AUTOSAR XML (schema 00047)
# (C) 2021 HYUNDAI AUTOEVER Corp.
package /Csm/ClientServerInterfaces
  6 x client server interface, all with is-service=true:
    CallbackNotification  # Interface for the callback notification.
      operation CallbackNotification  # Notifies the application with a return value that the job has finished.
        arg result: type=Csm_ResultType, direction=IN  # Return value that shall be returned to the application
    CsmKeyManagement_CryptoKey_Dummy  # Interface to execute the key management functions.
      11 x operation:
        KeyCopy: possible-error=[CsmKeyManagement_CryptoKey_Dummy/CSM_E_BUSY, CsmKeyManagement_CryptoKey_Dummy/CSM_E_KEY_EMPTY, CsmKeyManagement_CryptoKey_Dummy/CSM_E_KEY_NOT_AVAILABLE, CsmKeyManagement_CryptoKey_Dummy/CSM_E_KEY_READ_FAIL, CsmKeyManagement_CryptoKey_Dummy/CSM_E_KEY_SIZE_MISMATCH, CsmKeyManagement_CryptoKey_Dummy/CSM_E_KEY_WRITE_FAIL, CsmKeyManagement_CryptoKey_Dummy/E_NOT_OK, CsmKeyManagement_CryptoKey_Dummy/E_OK]  # This function shall copy all key elements from the source key to a target key.
          arg targetKeyId: type=uint32, direction=IN  # Holds the identifier of the key whose key element shall be the destination element.
        KeyDerive: possible-error=[CsmKeyManagement_CryptoKey_Dummy/CSM_E_BUSY, CsmKeyManagement_CryptoKey_Dummy/CSM_E_KEY_EMPTY, CsmKeyManagement_CryptoKey_Dummy/CSM_E_KEY_READ_FAIL, CsmKeyManagement_CryptoKey_Dummy/CSM_E_KEY_SIZE_MISMATCH, CsmKeyManagement_CryptoKey_Dummy/CSM_E_KEY_WRITE_FAIL, CsmKeyManagement_CryptoKey_Dummy/E_NOT_OK, CsmKeyManagement_CryptoKey_Dummy/E_OK]  # Derives a new key by using the key elements in the given key. The given key contains the key elements for the password and salt. The derived key is stored in the key element with the id 1 of the key identified by targetCryptoKeyId.
          arg targetKeyId: type=uint32, direction=IN  # Holds the identifier of the key which is used to store the derived key.
        KeyElementCopy: possible-error=[CsmKeyManagement_CryptoKey_Dummy/CSM_E_BUSY, CsmKeyManagement_CryptoKey_Dummy/CSM_E_KEY_EMPTY, CsmKeyManagement_CryptoKey_Dummy/CSM_E_KEY_NOT_AVAILABLE, CsmKeyManagement_CryptoKey_Dummy/CSM_E_KEY_READ_FAIL, CsmKeyManagement_CryptoKey_Dummy/CSM_E_KEY_SIZE_MISMATCH, CsmKeyManagement_CryptoKey_Dummy/CSM_E_KEY_WRITE_FAIL, CsmKeyManagement_CryptoKey_Dummy/E_NOT_OK, CsmKeyManagement_CryptoKey_Dummy/E_OK]  # This function shall copy a key elements from one key to a target key
          arg keyElementId: type=uint32, direction=IN  # Holds the identifier of the key element which shall be the source for the copy operation.
          arg targetKeyId: type=uint32, direction=IN  # Holds the identifier of the key whose key element shall be the destination element.
          arg targetKeyElementId: type=uint32, direction=IN  # Holds the identifier of the key element which shall be the destination for the copy operation.
        KeyElementCopyPartial: possible-error=[CsmKeyManagement_CryptoKey_Dummy/CSM_E_BUSY, CsmKeyManagement_CryptoKey_Dummy/CSM_E_KEY_EMPTY, CsmKeyManagement_CryptoKey_Dummy/CSM_E_KEY_NOT_AVAILABLE, CsmKeyManagement_CryptoKey_Dummy/CSM_E_KEY_READ_FAIL, CsmKeyManagement_CryptoKey_Dummy/CSM_E_KEY_SIZE_MISMATCH, CsmKeyManagement_CryptoKey_Dummy/CSM_E_KEY_WRITE_FAIL, CsmKeyManagement_CryptoKey_Dummy/E_NOT_OK, CsmKeyManagement_CryptoKey_Dummy/E_OK]  # This function shall copy parts of a a key elements from one key to parts of a target key element of a target key.
          6 x arg, all with type=uint32, direction=IN:
            keyElementId  # Holds the identifier of the key element which shall be the source for the copy operation.
            keyElementSourceOffset  # This is the offset of the source key element indicating the start index of the copy operation.
            keyElementTargetOffset  # This is the offset of the destination key element indicating the start index of the copy operation.
            keyElementCopyLength  # Specifies the number of bytes that shall be copied.
            targetKeyId  # Holds the identifier of the key whose key element shall be the destination element.
            targetKeyElementId  # Holds the identifier of the key element which shall be the destination for the copy operation.
        KeyElementGet: possible-error=[CsmKeyManagement_CryptoKey_Dummy/CSM_E_BUSY, CsmKeyManagement_CryptoKey_Dummy/CSM_E_KEY_EMPTY, CsmKeyManagement_CryptoKey_Dummy/CSM_E_KEY_NOT_AVAILABLE, CsmKeyManagement_CryptoKey_Dummy/CSM_E_KEY_READ_FAIL, CsmKeyManagement_CryptoKey_Dummy/CSM_E_SMALL_BUFFER, CsmKeyManagement_CryptoKey_Dummy/E_NOT_OK, CsmKeyManagement_CryptoKey_Dummy/E_OK]  # Retrieves the key element bytes from a specific key element of the key and stores the key element in the provided buffer.
          arg keyElementId: type=uint32, direction=IN  # Holds the identifier of the key element to be read.
          arg keyPtr: type=uint8, direction=OUT  # Holds the data to the key element bytes to be written.
          arg keyLength: type=uint32, direction=INOUT  # Contains the number of key element bytes.
        KeyElementSet: possible-error=[CsmKeyManagement_CryptoKey_Dummy/CSM_E_BUSY, CsmKeyManagement_CryptoKey_Dummy/CSM_E_KEY_NOT_AVAILABLE, CsmKeyManagement_CryptoKey_Dummy/CSM_E_KEY_SIZE_MISMATCH, CsmKeyManagement_CryptoKey_Dummy/CSM_E_KEY_WRITE_FAIL, CsmKeyManagement_CryptoKey_Dummy/E_NOT_OK, CsmKeyManagement_CryptoKey_Dummy/E_OK]  # Sets the given key element bytes to the key.
          arg keyElementId: type=uint32, direction=IN  # Holds the identifier of the key element to be written.
          arg keyPtr: type=Csm_ConstDataPtr, direction=IN  # Holds the data to the key element bytes to be processed.
          arg keyLength: type=uint32, direction=IN  # Contains the number of key element bytes.
        KeyExchangeCalcPubVal: possible-error=[CsmKeyManagement_CryptoKey_Dummy/CSM_E_BUSY, CsmKeyManagement_CryptoKey_Dummy/CSM_E_KEY_EMPTY, CsmKeyManagement_CryptoKey_Dummy/CSM_E_SMALL_BUFFER, CsmKeyManagement_CryptoKey_Dummy/E_NOT_OK, CsmKeyManagement_CryptoKey_Dummy/E_OK]  # Calculates the public value of the current user for the key exchange and stores the public key in the provided buffer
          arg publicValuePtr: type=uint8, direction=OUT  # Holds a pointer to the memory location in which the public value length in bytes is stored. On calling this function, this parameter shall contain the size of the buffer in bytes provided by publicValuePtr. When the request has finished, the actual length of the returned value shall be stored.
          arg publicValueLengthPtr: type=uint32, direction=INOUT  # Contains the pointer to the data where the public value shall be stored.
        KeyExchangeCalcSecret: possible-error=[CsmKeyManagement_CryptoKey_Dummy/CSM_E_BUSY, CsmKeyManagement_CryptoKey_Dummy/CSM_E_KEY_EMPTY, CsmKeyManagement_CryptoKey_Dummy/CSM_E_SMALL_BUFFER, CsmKeyManagement_CryptoKey_Dummy/E_NOT_OK, CsmKeyManagement_CryptoKey_Dummy/E_OK]  # Calculates the shared secret key for the key exchange with the key material of the key identified by the keyId and the partner public key. The shared secret key is stored as a key element in the same key.
          arg partnerPublicValuePtr: type=Csm_ConstDataPtr, direction=IN  # Holds the pointer to the memory location containing the partner's public value
          arg partnerPublicValueLength: type=uint32, direction=IN  # Contains the number of bytes of the partner pulic value
        KeyGenerate: possible-error=[CsmKeyManagement_CryptoKey_Dummy/CSM_E_BUSY, CsmKeyManagement_CryptoKey_Dummy/CSM_E_KEY_EMPTY, CsmKeyManagement_CryptoKey_Dummy/E_NOT_OK, CsmKeyManagement_CryptoKey_Dummy/E_OK]  # Generates new key material and store it in the key identified by keyId.
        KeySetValid: possible-error=[CsmKeyManagement_CryptoKey_Dummy/CSM_E_BUSY, CsmKeyManagement_CryptoKey_Dummy/E_NOT_OK, CsmKeyManagement_CryptoKey_Dummy/E_OK]  # Sets the given key element bytes to the key.
        RandomSeed: possible-error=[CsmKeyManagement_CryptoKey_Dummy/CSM_E_BUSY, CsmKeyManagement_CryptoKey_Dummy/E_NOT_OK, CsmKeyManagement_CryptoKey_Dummy/E_OK]  # Feeds the key element CRYPTO_KE_RANDOM_SEED with a random seed.
          arg seedPtr: type=Csm_ConstDataPtr, direction=IN  # Holds the data which shall be used for the random seed initialization.
          arg seedLength: type=uint32, direction=IN  # Contains the length of the seed in bytes.
      9 x error:
        CSM_E_BUSY: error-code=2  # Request failed, service is still busy.
        CSM_E_KEY_EMPTY: error-code=13  # The service request failed because of uninitialized source key element.
        CSM_E_KEY_NOT_AVAILABLE: error-code=8  # The service request failed because the key is not available.
        CSM_E_KEY_READ_FAIL: error-code=6  # The service request failed because read access was denied.
        CSM_E_KEY_SIZE_MISMATCH: error-code=10  # Request failed because the key element is not partially accessible and the provided key element length is too short or too long for that key element.
        CSM_E_KEY_WRITE_FAIL: error-code=7  # The service request failed because write access was denied.
        CSM_E_SMALL_BUFFER: error-code=3  # The provided buffer is too small to store the result.
        E_NOT_OK: error-code=1  # Operation failed
        E_OK: error-code=0  # Operation successful
    CsmKeyManagement_CryptoKey_OEUK  # Interface to execute the key management functions.
      11 x operation:
        KeyCopy: possible-error=[CsmKeyManagement_CryptoKey_OEUK/CSM_E_BUSY, CsmKeyManagement_CryptoKey_OEUK/CSM_E_KEY_EMPTY, CsmKeyManagement_CryptoKey_OEUK/CSM_E_KEY_NOT_AVAILABLE, CsmKeyManagement_CryptoKey_OEUK/CSM_E_KEY_READ_FAIL, CsmKeyManagement_CryptoKey_OEUK/CSM_E_KEY_SIZE_MISMATCH, CsmKeyManagement_CryptoKey_OEUK/CSM_E_KEY_WRITE_FAIL, CsmKeyManagement_CryptoKey_OEUK/E_NOT_OK, CsmKeyManagement_CryptoKey_OEUK/E_OK]  # This function shall copy all key elements from the source key to a target key.
          arg targetKeyId: type=uint32, direction=IN  # Holds the identifier of the key whose key element shall be the destination element.
        KeyDerive: possible-error=[CsmKeyManagement_CryptoKey_OEUK/CSM_E_BUSY, CsmKeyManagement_CryptoKey_OEUK/CSM_E_KEY_EMPTY, CsmKeyManagement_CryptoKey_OEUK/CSM_E_KEY_READ_FAIL, CsmKeyManagement_CryptoKey_OEUK/CSM_E_KEY_SIZE_MISMATCH, CsmKeyManagement_CryptoKey_OEUK/CSM_E_KEY_WRITE_FAIL, CsmKeyManagement_CryptoKey_OEUK/E_NOT_OK, CsmKeyManagement_CryptoKey_OEUK/E_OK]  # Derives a new key by using the key elements in the given key. The given key contains the key elements for the password and salt. The derived key is stored in the key element with the id 1 of the key identified by targetCryptoKeyId.
          arg targetKeyId: type=uint32, direction=IN  # Holds the identifier of the key which is used to store the derived key.
        KeyElementCopy: possible-error=[CsmKeyManagement_CryptoKey_OEUK/CSM_E_BUSY, CsmKeyManagement_CryptoKey_OEUK/CSM_E_KEY_EMPTY, CsmKeyManagement_CryptoKey_OEUK/CSM_E_KEY_NOT_AVAILABLE, CsmKeyManagement_CryptoKey_OEUK/CSM_E_KEY_READ_FAIL, CsmKeyManagement_CryptoKey_OEUK/CSM_E_KEY_SIZE_MISMATCH, CsmKeyManagement_CryptoKey_OEUK/CSM_E_KEY_WRITE_FAIL, CsmKeyManagement_CryptoKey_OEUK/E_NOT_OK, CsmKeyManagement_CryptoKey_OEUK/E_OK]  # This function shall copy a key elements from one key to a target key
          arg keyElementId: type=uint32, direction=IN  # Holds the identifier of the key element which shall be the source for the copy operation.
          arg targetKeyId: type=uint32, direction=IN  # Holds the identifier of the key whose key element shall be the destination element.
          arg targetKeyElementId: type=uint32, direction=IN  # Holds the identifier of the key element which shall be the destination for the copy operation.
        KeyElementCopyPartial: possible-error=[CsmKeyManagement_CryptoKey_OEUK/CSM_E_BUSY, CsmKeyManagement_CryptoKey_OEUK/CSM_E_KEY_EMPTY, CsmKeyManagement_CryptoKey_OEUK/CSM_E_KEY_NOT_AVAILABLE, CsmKeyManagement_CryptoKey_OEUK/CSM_E_KEY_READ_FAIL, CsmKeyManagement_CryptoKey_OEUK/CSM_E_KEY_SIZE_MISMATCH, CsmKeyManagement_CryptoKey_OEUK/CSM_E_KEY_WRITE_FAIL, CsmKeyManagement_CryptoKey_OEUK/E_NOT_OK, CsmKeyManagement_CryptoKey_OEUK/E_OK]  # This function shall copy parts of a a key elements from one key to parts of a target key element of a target key.
          6 x arg, all with type=uint32, direction=IN:
            keyElementId  # Holds the identifier of the key element which shall be the source for the copy operation.
            keyElementSourceOffset  # This is the offset of the source key element indicating the start index of the copy operation.
            keyElementTargetOffset  # This is the offset of the destination key element indicating the start index of the copy operation.
            keyElementCopyLength  # Specifies the number of bytes that shall be copied.
            targetKeyId  # Holds the identifier of the key whose key element shall be the destination element.
            targetKeyElementId  # Holds the identifier of the key element which shall be the destination for the copy operation.
        KeyElementGet: possible-error=[CsmKeyManagement_CryptoKey_OEUK/CSM_E_BUSY, CsmKeyManagement_CryptoKey_OEUK/CSM_E_KEY_EMPTY, CsmKeyManagement_CryptoKey_OEUK/CSM_E_KEY_NOT_AVAILABLE, CsmKeyManagement_CryptoKey_OEUK/CSM_E_KEY_READ_FAIL, CsmKeyManagement_CryptoKey_OEUK/CSM_E_SMALL_BUFFER, CsmKeyManagement_CryptoKey_OEUK/E_NOT_OK, CsmKeyManagement_CryptoKey_OEUK/E_OK]  # Retrieves the key element bytes from a specific key element of the key and stores the key element in the provided buffer.
          arg keyElementId: type=uint32, direction=IN  # Holds the identifier of the key element to be read.
          arg keyPtr: type=uint8, direction=OUT  # Holds the data to the key element bytes to be written.
          arg keyLength: type=uint32, direction=INOUT  # Contains the number of key element bytes.
        KeyElementSet: possible-error=[CsmKeyManagement_CryptoKey_OEUK/CSM_E_BUSY, CsmKeyManagement_CryptoKey_OEUK/CSM_E_KEY_NOT_AVAILABLE, CsmKeyManagement_CryptoKey_OEUK/CSM_E_KEY_SIZE_MISMATCH, CsmKeyManagement_CryptoKey_OEUK/CSM_E_KEY_WRITE_FAIL, CsmKeyManagement_CryptoKey_OEUK/E_NOT_OK, CsmKeyManagement_CryptoKey_OEUK/E_OK]  # Sets the given key element bytes to the key.
          arg keyElementId: type=uint32, direction=IN  # Holds the identifier of the key element to be written.
          arg keyPtr: type=Csm_ConstDataPtr, direction=IN  # Holds the data to the key element bytes to be processed.
          arg keyLength: type=uint32, direction=IN  # Contains the number of key element bytes.
        KeyExchangeCalcPubVal: possible-error=[CsmKeyManagement_CryptoKey_OEUK/CSM_E_BUSY, CsmKeyManagement_CryptoKey_OEUK/CSM_E_KEY_EMPTY, CsmKeyManagement_CryptoKey_OEUK/CSM_E_SMALL_BUFFER, CsmKeyManagement_CryptoKey_OEUK/E_NOT_OK, CsmKeyManagement_CryptoKey_OEUK/E_OK]  # Calculates the public value of the current user for the key exchange and stores the public key in the provided buffer
          arg publicValuePtr: type=uint8, direction=OUT  # Holds a pointer to the memory location in which the public value length in bytes is stored. On calling this function, this parameter shall contain the size of the buffer in bytes provided by publicValuePtr. When the request has finished, the actual length of the returned value shall be stored.
          arg publicValueLengthPtr: type=uint32, direction=INOUT  # Contains the pointer to the data where the public value shall be stored.
        KeyExchangeCalcSecret: possible-error=[CsmKeyManagement_CryptoKey_OEUK/CSM_E_BUSY, CsmKeyManagement_CryptoKey_OEUK/CSM_E_KEY_EMPTY, CsmKeyManagement_CryptoKey_OEUK/CSM_E_SMALL_BUFFER, CsmKeyManagement_CryptoKey_OEUK/E_NOT_OK, CsmKeyManagement_CryptoKey_OEUK/E_OK]  # Calculates the shared secret key for the key exchange with the key material of the key identified by the keyId and the partner public key. The shared secret key is stored as a key element in the same key.
          arg partnerPublicValuePtr: type=Csm_ConstDataPtr, direction=IN  # Holds the pointer to the memory location containing the partner's public value
          arg partnerPublicValueLength: type=uint32, direction=IN  # Contains the number of bytes of the partner pulic value
        KeyGenerate: possible-error=[CsmKeyManagement_CryptoKey_OEUK/CSM_E_BUSY, CsmKeyManagement_CryptoKey_OEUK/CSM_E_KEY_EMPTY, CsmKeyManagement_CryptoKey_OEUK/E_NOT_OK, CsmKeyManagement_CryptoKey_OEUK/E_OK]  # Generates new key material and store it in the key identified by keyId.
        KeySetValid: possible-error=[CsmKeyManagement_CryptoKey_OEUK/CSM_E_BUSY, CsmKeyManagement_CryptoKey_OEUK/E_NOT_OK, CsmKeyManagement_CryptoKey_OEUK/E_OK]  # Sets the given key element bytes to the key.
        RandomSeed: possible-error=[CsmKeyManagement_CryptoKey_OEUK/CSM_E_BUSY, CsmKeyManagement_CryptoKey_OEUK/E_NOT_OK, CsmKeyManagement_CryptoKey_OEUK/E_OK]  # Feeds the key element CRYPTO_KE_RANDOM_SEED with a random seed.
          arg seedPtr: type=Csm_ConstDataPtr, direction=IN  # Holds the data which shall be used for the random seed initialization.
          arg seedLength: type=uint32, direction=IN  # Contains the length of the seed in bytes.
      9 x error:
        CSM_E_BUSY: error-code=2  # Request failed, service is still busy.
        CSM_E_KEY_EMPTY: error-code=13  # The service request failed because of uninitialized source key element.
        CSM_E_KEY_NOT_AVAILABLE: error-code=8  # The service request failed because the key is not available.
        CSM_E_KEY_READ_FAIL: error-code=6  # The service request failed because read access was denied.
        CSM_E_KEY_SIZE_MISMATCH: error-code=10  # Request failed because the key element is not partially accessible and the provided key element length is too short or too long for that key element.
        CSM_E_KEY_WRITE_FAIL: error-code=7  # The service request failed because write access was denied.
        CSM_E_SMALL_BUFFER: error-code=3  # The provided buffer is too small to store the result.
        E_NOT_OK: error-code=1  # Operation failed
        E_OK: error-code=0  # Operation successful
    CsmRandomGenerate_HaeHsmRandomGenerate_L9  # Synchronous processing interface to execute the random number generation.
      operation RandomGenerate: possible-error=[CsmRandomGenerate_HaeHsmRandomGenerate_L9/CSM_E_BUSY, CsmRandomGenerate_HaeHsmRandomGenerate_L9/CSM_E_ENTROPY_EXHAUSTION, CsmRandomGenerate_HaeHsmRandomGenerate_L9/E_NOT_OK, CsmRandomGenerate_HaeHsmRandomGenerate_L9/E_OK]  # Synchronous processing interface to execute the random number generation.
        arg resultBuffer: type=uint8, direction=OUT  # Contains the random number
        arg resultLength: type=uint32, direction=INOUT  # Contains the length in bytes of the data of random number.
      4 x error:
        CSM_E_BUSY: error-code=2  # Request failed, service is still busy.
        CSM_E_ENTROPY_EXHAUSTION: error-code=4  # Request failed, entropy of random number generator is exhausted.
        E_NOT_OK: error-code=1  # Operation failed
        E_OK: error-code=0  # Operation successful
    CsmSignatureVerify  # Asynchronous processing interface to execute the signature verification.
      operation CancelJob: possible-error=[CSM_E_JOB_CANCELED, CsmSignatureVerify/E_NOT_OK, CsmSignatureVerify/E_OK]  # Cancels the job.
        arg mode: type=Crypto_OperationModeType, direction=IN  # indicates which operation mode(s) to perform
      operation SignatureVerify: possible-error=[CsmSignatureVerify/CSM_E_BUSY, CsmSignatureVerify/CSM_E_KEY_EMPTY, CSM_E_KEY_NOT_VALID, CsmSignatureVerify/CSM_E_KEY_SIZE_MISMATCH, CsmSignatureVerify/CSM_E_SMALL_BUFFER, CsmSignatureVerify/E_NOT_OK, CsmSignatureVerify/E_OK]  # Operation to verify a signature.
        6 x arg:
          mode: type=Crypto_OperationModeType, direction=IN  # indicates which operation mode(s) to perform
          dataBuffer: type=Csm_ConstDataPtr, direction=IN  # References the data for which signature shall be verified.
          dataLength: type=uint32, direction=IN  # Contains the length in bytes of the data for which signature shall be verified.
          compareBuffer: type=Csm_ConstDataPtr, direction=IN  # References the signature to be verified.
          compareLength: type=uint32, direction=IN  # Contains the length in bytes of the signature to be verified.
          resultBuffer: type=Crypto_VerifyResultType, direction=OUT  # Contains the verification result.
      8 x error:
        CSM_E_BUSY: error-code=2  # Request failed, service is still busy.
        CSM_E_JOB_CANCELED: error-code=12  # Request failed because the job has been canceled.
        CSM_E_KEY_EMPTY: error-code=13  # The service request failed because of uninitialized source key element.
        CSM_E_KEY_NOT_VALID: error-code=9  # Request failed, the key is not valid.
        CSM_E_KEY_SIZE_MISMATCH: error-code=10  # Request failed because the key element is not partially accessible and the provided key element length is too short or too long for that key element.
        CSM_E_SMALL_BUFFER: error-code=3  # The provided buffer is too small to store the result.
        E_NOT_OK: error-code=1  # Operation failed
        E_OK: error-code=0  # Operation successful
    HaeHsmRandomGenerate_L10_RandomGenerate_L10  # Synchronous processing interface to execute the random number generation.
      operation RandomGenerate: possible-error=[HaeHsmRandomGenerate_L10_RandomGenerate_L10/CSM_E_BUSY, HaeHsmRandomGenerate_L10_RandomGenerate_L10/CSM_E_ENTROPY_EXHAUSTION, HaeHsmRandomGenerate_L10_RandomGenerate_L10/E_NOT_OK, HaeHsmRandomGenerate_L10_RandomGenerate_L10/E_OK]  # Synchronous processing interface to execute the random number generation.
        arg resultBuffer: type=uint8, direction=OUT  # Contains the random number
        arg resultLength: type=uint32, direction=INOUT  # Contains the length in bytes of the data of random number.
      4 x error:
        CSM_E_BUSY: error-code=2  # Request failed, service is still busy.
        CSM_E_ENTROPY_EXHAUSTION: error-code=4  # Request failed, entropy of random number generator is exhausted.
        E_NOT_OK: error-code=1  # Operation failed
        E_OK: error-code=0  # Operation successful
package /Csm/CompuMethods
  compu method Csm_JobIdTypeValue: 0=CSM_RandomGenerate_L9, 1=CSM_Hash_Sha256_Fota, 2=CSM_SignatureVerify_RSASSA_PKCS1_v1_5_Fota, 3=CSM_Fota_Decrypt0, 4=CSM_Fota_MacVerify0, 5=CSM_RandomGenerate_L10, 6=CSM_SignatureVerify_RSASSA_PKCS1_v1_5
  compu method Csm_KeyIdTypeValue: 0=CSM_RandomSeed_L9, 1=CSM_Hash_Dummy_Fota, 2=CSM_Pkcs1_Asims_Public_key, 3=CSM_Fota_Decrypt0Key, 4=CSM_Fota_MacVerify0Key, 5=CSM_PBKDF2_Key, 6=CSM_PBKDF2_TargetKey, 7=CSM_CryptoKey_Dummy, 8=CSM_RandomSeed_L10, 9=CSM_CryptoKey_OEUK
package /Csm/ImplementationDataTypes
  28 x impl type:
    Crypto_OperationModeType: category=VALUE, base-type=uint8, compu {0x01=CRYPTO_OPERATIONMODE_START, 0x02=CRYPTO_OPERATIONMODE_UPDATE, 0x03=CRYPTO_OPERATIONMODE_STREAMSTART, 0x04=CRYPTO_OPERATIONMODE_FINISH, 0x07=CRYPTO_OPERATIONMODE_SINGLECALL}, range raw 0x01..0x07
    Crypto_VerifyResultType: category=VALUE, base-type=uint8, compu {0x00=CRYPTO_E_VER_OK, 0x01=CRYPTO_E_VER_NOT_OK}, range raw 0x00..0x01
    Csm_ConstDataPtr: category=DATA_REFERENCE, sw-pointer-target-props={target-category=VALUE, base-type=uint8, sw-impl-policy=CONST}
    Csm_DataPtr: category=DATA_REFERENCE, sw-pointer-target-props={target-category=VALUE, base-type=uint8}
    Csm_DecryptDataType_Crypto_SW: category=ARRAY
      element Csm_DecryptDataType: array-size=2048, array-size-semantics=FIXED-SIZE, implementation-data-type=uint8
    Csm_DecryptResultType_Crypto_SW: category=ARRAY
      element Csm_DecryptResultType: array-size=2048, array-size-semantics=FIXED-SIZE, implementation-data-type=uint8
    Csm_HashDataType_Crypto_SW: category=ARRAY
      element Csm_HashDataType: array-size=64, array-size-semantics=FIXED-SIZE, implementation-data-type=uint8
    Csm_HashResultType_Crypto_SW: category=ARRAY
      element Csm_HashResultType: array-size=32, array-size-semantics=FIXED-SIZE, implementation-data-type=uint8
    Csm_KeyDataType_CryptoKey_Dummy: category=ARRAY
      element Csm_KeyDataType: array-size=32, array-size-semantics=FIXED-SIZE, implementation-data-type=uint8
    Csm_KeyDataType_CryptoKey_OEUK: category=ARRAY
      element Csm_KeyDataType: array-size=260, array-size-semantics=FIXED-SIZE, implementation-data-type=uint8
    Csm_KeyDataType_Fota_Decrypt0Key: category=ARRAY
      element Csm_KeyDataType: array-size=16, array-size-semantics=FIXED-SIZE, implementation-data-type=uint8
    Csm_KeyDataType_Fota_MacVerify0Key: category=ARRAY
      element Csm_KeyDataType: array-size=16, array-size-semantics=FIXED-SIZE, implementation-data-type=uint8
    Csm_KeyDataType_Hash_Dummy_Fota: category=ARRAY
      element Csm_KeyDataType: array-size=32, array-size-semantics=FIXED-SIZE, implementation-data-type=uint8
    Csm_KeyDataType_PBKDF2_Key: category=ARRAY
      element Csm_KeyDataType: array-size=48, array-size-semantics=FIXED-SIZE, implementation-data-type=uint8
    Csm_KeyDataType_PBKDF2_TargetKey: category=ARRAY
      element Csm_KeyDataType: array-size=32, array-size-semantics=FIXED-SIZE, implementation-data-type=uint8
    Csm_KeyDataType_Pkcs1_Asims_Public_key: category=ARRAY
      element Csm_KeyDataType: array-size=260, array-size-semantics=FIXED-SIZE, implementation-data-type=uint8
    Csm_KeyDataType_RandomSeed_L10: category=ARRAY
      element Csm_KeyDataType: array-size=16, array-size-semantics=FIXED-SIZE, implementation-data-type=uint8
    Csm_KeyDataType_RandomSeed_L9: category=ARRAY
      element Csm_KeyDataType: array-size=16, array-size-semantics=FIXED-SIZE, implementation-data-type=uint8
    Csm_LengthPtr: category=DATA_REFERENCE, sw-pointer-target-props={target-category=TYPE_REFERENCE, implementation-data-type=uint32}
    Csm_MacVerifyCompareType_Crypto_SW: category=ARRAY
      element Csm_MacVerifyCompareType: array-size=16, array-size-semantics=FIXED-SIZE, implementation-data-type=uint8
    Csm_RandomGenerateResultType_Crypto_HSM: category=ARRAY
      element Csm_RandomGenerateResultType: array-size=8, array-size-semantics=FIXED-SIZE, implementation-data-type=uint8
    Csm_RandomGenerateResultType_Crypto_OEUK: category=ARRAY
      element Csm_RandomGenerateResultType: array-size=8, array-size-semantics=FIXED-SIZE, implementation-data-type=uint8
    Csm_ResultType: category=VALUE, base-type=uint8, compu {0x02=E_SMALL_BUFFER, 0x03=E_ENTROPY_EXHAUSTION, 0x04=E_KEY_READ_FAIL, 0x05=E_KEY_NOT_AVAILABLE, 0x06=E_KEY_NOT_VALID, 0x07=E_JOB_CANCELED, 0x00=E_OK, 0x01=E_NOT_OK, 0x08=E_KEY_EMPTY}, range raw 0x00..0x08
    Csm_SignatureVerifyCompareType_Crypto_OEUK: category=ARRAY
      element Csm_SignatureVerifyCompareType: array-size=8, array-size-semantics=FIXED-SIZE, implementation-data-type=uint8
    Csm_SignatureVerifyCompareType_Crypto_SW: category=ARRAY
      element Csm_SignatureVerifyCompareType: array-size=256, array-size-semantics=FIXED-SIZE, implementation-data-type=uint8
    Csm_SignatureVerifyDataType_Crypto_OEUK: category=ARRAY
      element Csm_SignatureVerifyDataType: array-size=3, array-size-semantics=FIXED-SIZE, implementation-data-type=uint8
    Csm_SignatureVerifyDataType_Crypto_SW: category=ARRAY
      element Csm_SignatureVerifyDataType: array-size=4096, array-size-semantics=FIXED-SIZE, implementation-data-type=uint8
    Csm_VerifyResultPtr: category=DATA_REFERENCE, sw-pointer-target-props={target-category=TYPE_REFERENCE, implementation-data-type=Crypto_VerifyResultType}
package /Csm/ServiceSwComponentTypes
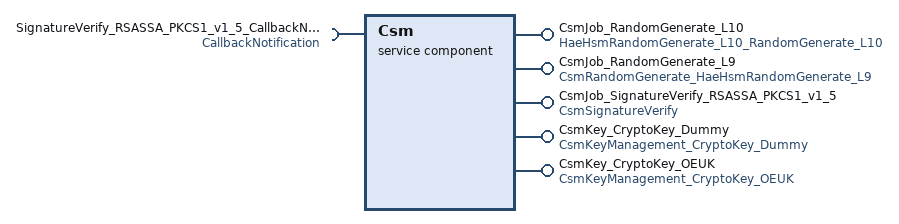
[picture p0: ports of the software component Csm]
  service sw component type Csm
    5 x provide port:
      CsmJob_RandomGenerate_L10: server-com-spec{operation=HaeHsmRandomGenerate_L10_RandomGenerate_L10/RandomGenerate, queue-length=1}, provided-interface=HaeHsmRandomGenerate_L10_RandomGenerate_L10  # Port related to a specific cryptographic job to execute the assigned cryptographic calculations synchronously.
      CsmJob_RandomGenerate_L9: server-com-spec{operation=CsmRandomGenerate_HaeHsmRandomGenerate_L9/RandomGenerate, queue-length=1}, provided-interface=CsmRandomGenerate_HaeHsmRandomGenerate_L9  # Port related to a specific cryptographic job to execute the assigned cryptographic calculations synchronously.
      CsmJob_SignatureVerify_RSASSA_PKCS1_v1_5: provided-com-specs=[{operation=CancelJob, queue-length=1}, {operation=SignatureVerify, queue-length=1}], provided-interface=CsmSignatureVerify  # Port related to a specific cryptographic job to execute the assigned cryptographic calculations asynchronously.
      CsmKey_CryptoKey_Dummy: provided-interface=CsmKeyManagement_CryptoKey_Dummy  # Port related to a specific cryptographic key to execute the key management functions synchronously.
        provided-com-specs:
          operation=CsmKeyManagement_CryptoKey_Dummy/KeyCopy, queue-length=1
          operation=CsmKeyManagement_CryptoKey_Dummy/KeyDerive, queue-length=1
          operation=CsmKeyManagement_CryptoKey_Dummy/KeyElementCopy, queue-length=1
          operation=CsmKeyManagement_CryptoKey_Dummy/KeyElementCopyPartial, queue-length=1
          operation=CsmKeyManagement_CryptoKey_Dummy/KeyElementGet, queue-length=1
          operation=CsmKeyManagement_CryptoKey_Dummy/KeyElementSet, queue-length=1
          operation=CsmKeyManagement_CryptoKey_Dummy/KeyExchangeCalcPubVal, queue-length=1
          operation=CsmKeyManagement_CryptoKey_Dummy/KeyExchangeCalcSecret, queue-length=1
          operation=CsmKeyManagement_CryptoKey_Dummy/KeyGenerate, queue-length=1
          operation=CsmKeyManagement_CryptoKey_Dummy/KeySetValid, queue-length=1
          operation=CsmKeyManagement_CryptoKey_Dummy/RandomSeed, queue-length=1
      CsmKey_CryptoKey_OEUK: provided-interface=CsmKeyManagement_CryptoKey_OEUK  # Port related to a specific cryptographic key to execute the key management functions synchronously.
        provided-com-specs:
          operation=CsmKeyManagement_CryptoKey_OEUK/KeyCopy, queue-length=1
          operation=CsmKeyManagement_CryptoKey_OEUK/KeyDerive, queue-length=1
          operation=CsmKeyManagement_CryptoKey_OEUK/KeyElementCopy, queue-length=1
          operation=CsmKeyManagement_CryptoKey_OEUK/KeyElementCopyPartial, queue-length=1
          operation=CsmKeyManagement_CryptoKey_OEUK/KeyElementGet, queue-length=1
          operation=CsmKeyManagement_CryptoKey_OEUK/KeyElementSet, queue-length=1
          operation=CsmKeyManagement_CryptoKey_OEUK/KeyExchangeCalcPubVal, queue-length=1
          operation=CsmKeyManagement_CryptoKey_OEUK/KeyExchangeCalcSecret, queue-length=1
          operation=CsmKeyManagement_CryptoKey_OEUK/KeyGenerate, queue-length=1
          operation=CsmKeyManagement_CryptoKey_OEUK/KeySetValid, queue-length=1
          operation=CsmKeyManagement_CryptoKey_OEUK/RandomSeed, queue-length=1
    require port SignatureVerify_RSASSA_PKCS1_v1_5_CallbackNotification: client-com-spec=CallbackNotification, required-interface=CallbackNotification  # Port for the callback notification.
    behavior CsmInternalBehavior: handle-termination-and-restart=NO-SUPPORT, included-data-type-sets=[data-type=Crypto_OperationModeType, data-type=Crypto_VerifyResultType, data-type=Csm_ResultType]
      26 x operation invoked event:
        OperationInvokedEvent_CsmJob_RandomGenerate_L10_RandomGenerate: start-on-event=RandomGenerate, operation=CsmJob_RandomGenerate_L10.RandomGenerate
        OperationInvokedEvent_CsmJob_RandomGenerate_L9_RandomGenerate: start-on-event=RandomGenerate, operation=CsmJob_RandomGenerate_L9.RandomGenerate
        OperationInvokedEvent_CsmJob_SignatureVerify_RSASSA_PKCS1_v1_5_CancelJob: start-on-event=CancelJob, operation=CsmJob_SignatureVerify_RSASSA_PKCS1_v1_5.CancelJob
        OperationInvokedEvent_CsmJob_SignatureVerify_RSASSA_PKCS1_v1_5_SignatureVerify: start-on-event=SignatureVerify, operation=CsmJob_SignatureVerify_RSASSA_PKCS1_v1_5.SignatureVerify
        OperationInvokedEvent_CsmKey_CryptoKey_Dummy_KeyCopy: start-on-event=KeyCopy, operation=CsmKey_CryptoKey_Dummy.KeyCopy
        OperationInvokedEvent_CsmKey_CryptoKey_Dummy_KeyDerive: start-on-event=KeyDerive, operation=CsmKey_CryptoKey_Dummy.KeyDerive
        OperationInvokedEvent_CsmKey_CryptoKey_Dummy_KeyElementCopy: start-on-event=KeyElementCopy, operation=CsmKey_CryptoKey_Dummy.KeyElementCopy
        OperationInvokedEvent_CsmKey_CryptoKey_Dummy_KeyElementCopyPartial: start-on-event=KeyElementCopyPartial, operation=CsmKey_CryptoKey_Dummy.KeyElementCopyPartial
        OperationInvokedEvent_CsmKey_CryptoKey_Dummy_KeyElementGet: start-on-event=KeyElementGet, operation=CsmKey_CryptoKey_Dummy.KeyElementGet
        OperationInvokedEvent_CsmKey_CryptoKey_Dummy_KeyElementSet: start-on-event=KeyElementSet, operation=CsmKey_CryptoKey_Dummy.KeyElementSet
        OperationInvokedEvent_CsmKey_CryptoKey_Dummy_KeyExchangeCalcPubVal: start-on-event=KeyExchangeCalcPubVal, operation=CsmKey_CryptoKey_Dummy.KeyExchangeCalcPubVal
        OperationInvokedEvent_CsmKey_CryptoKey_Dummy_KeyExchangeCalcSecret: start-on-event=KeyExchangeCalcSecret, operation=CsmKey_CryptoKey_Dummy.KeyExchangeCalcSecret
        OperationInvokedEvent_CsmKey_CryptoKey_Dummy_KeyGenerate: start-on-event=KeyGenerate, operation=CsmKey_CryptoKey_Dummy.KeyGenerate
        OperationInvokedEvent_CsmKey_CryptoKey_Dummy_KeySetValid: start-on-event=KeySetValid, operation=CsmKey_CryptoKey_Dummy.KeySetValid
        OperationInvokedEvent_CsmKey_CryptoKey_Dummy_RandomSeed: start-on-event=RandomSeed, operation=CsmKey_CryptoKey_Dummy.RandomSeed
        OperationInvokedEvent_CsmKey_CryptoKey_OEUK_KeyCopy: start-on-event=KeyCopy, operation=CsmKey_CryptoKey_OEUK.KeyCopy
        OperationInvokedEvent_CsmKey_CryptoKey_OEUK_KeyDerive: start-on-event=KeyDerive, operation=CsmKey_CryptoKey_OEUK.KeyDerive
        OperationInvokedEvent_CsmKey_CryptoKey_OEUK_KeyElementCopy: start-on-event=KeyElementCopy, operation=CsmKey_CryptoKey_OEUK.KeyElementCopy
        OperationInvokedEvent_CsmKey_CryptoKey_OEUK_KeyElementCopyPartial: start-on-event=KeyElementCopyPartial, operation=CsmKey_CryptoKey_OEUK.KeyElementCopyPartial
        OperationInvokedEvent_CsmKey_CryptoKey_OEUK_KeyElementGet: start-on-event=KeyElementGet, operation=CsmKey_CryptoKey_OEUK.KeyElementGet
        OperationInvokedEvent_CsmKey_CryptoKey_OEUK_KeyElementSet: start-on-event=KeyElementSet, operation=CsmKey_CryptoKey_OEUK.KeyElementSet
        OperationInvokedEvent_CsmKey_CryptoKey_OEUK_KeyExchangeCalcPubVal: start-on-event=KeyExchangeCalcPubVal, operation=CsmKey_CryptoKey_OEUK.KeyExchangeCalcPubVal
        OperationInvokedEvent_CsmKey_CryptoKey_OEUK_KeyExchangeCalcSecret: start-on-event=KeyExchangeCalcSecret, operation=CsmKey_CryptoKey_OEUK.KeyExchangeCalcSecret
        OperationInvokedEvent_CsmKey_CryptoKey_OEUK_KeyGenerate: start-on-event=KeyGenerate, operation=CsmKey_CryptoKey_OEUK.KeyGenerate
        OperationInvokedEvent_CsmKey_CryptoKey_OEUK_KeySetValid: start-on-event=KeySetValid, operation=CsmKey_CryptoKey_OEUK.KeySetValid
        OperationInvokedEvent_CsmKey_CryptoKey_OEUK_RandomSeed: start-on-event=RandomSeed, operation=CsmKey_CryptoKey_OEUK.RandomSeed
      port-api-options:
        {enable-take-address=false, indirect-api=false, port-defined-argument-value{value=0, value-type=uint32}, port=CsmJob_RandomGenerate_L9}
        {enable-take-address=false, indirect-api=false, port-defined-argument-value{value=5, value-type=uint32}, port=CsmJob_RandomGenerate_L10}
        {enable-take-address=false, indirect-api=false, port-defined-argument-value{value=6, value-type=uint32}, port=CsmJob_SignatureVerify_RSASSA_PKCS1_v1_5}
        {enable-take-address=false, indirect-api=false, port-defined-argument-value{value=7, value-type=uint32}, port=CsmKey_CryptoKey_Dummy}
        {enable-take-address=false, indirect-api=false, port-defined-argument-value{value=9, value-type=uint32}, port=CsmKey_CryptoKey_OEUK}
      15 x runnable:
        CancelJob: symbol=Csm_CancelJob
        KeyCopy: can-be-invoked-concurrently=true, symbol=Csm_KeyCopy
        KeyDerive: can-be-invoked-concurrently=true, symbol=Csm_KeyDerive
        KeyElementCopy: can-be-invoked-concurrently=true, symbol=Csm_KeyElementCopy
        KeyElementCopyPartial: can-be-invoked-concurrently=true, symbol=Csm_KeyElementCopyPartial
        KeyElementGet: can-be-invoked-concurrently=true, symbol=Csm_KeyElementGet
        KeyElementSet: symbol=Csm_KeyElementSet
        KeyExchangeCalcPubVal: can-be-invoked-concurrently=true, symbol=Csm_KeyExchangeCalcPubVal
        KeyExchangeCalcSecret: can-be-invoked-concurrently=true, symbol=Csm_KeyExchangeCalcSecret
        KeyGenerate: can-be-invoked-concurrently=true, symbol=Csm_KeyGenerate
        KeySetValid: symbol=Csm_KeySetValid
        MainFunction: symbol=Csm_MainFunction
          sync call SSCP_CallbackNotification_SignatureVerify_RSASSA_PKCS1_v1_5_CallbackNotification_CallbackNotification: operation=SignatureVerify_RSASSA_PKCS1_v1_5_CallbackNotification.CallbackNotification
        RandomGenerate: can-be-invoked-concurrently=true, symbol=Csm_RandomGenerate
        RandomSeed: can-be-invoked-concurrently=true, symbol=Csm_RandomSeed
        SignatureVerify: can-be-invoked-concurrently=true, symbol=Csm_SignatureVerify
  swc bsw mapping SwcBswMapping_Csm: bsw-behavior=BswInternalBehavior_Csm, swc-behavior=CsmInternalBehavior
    runnable-mappings:
      bsw-entity=BswCE_Csm_KeyElementSet, swc-runnable=KeyElementSet
      bsw-entity=BswCE_Csm_KeySetValid, swc-runnable=KeySetValid
      bsw-entity=BswCE_Csm_KeyElementGet, swc-runnable=KeyElementGet
      bsw-entity=BswCE_Csm_KeyElementCopy, swc-runnable=KeyElementCopy
      bsw-entity=BswCE_Csm_KeyCopy, swc-runnable=KeyCopy
      bsw-entity=BswCE_Csm_KeyElementCopyPartial, swc-runnable=KeyElementCopyPartial
      bsw-entity=BswCE_Csm_RandomSeed, swc-runnable=RandomSeed
      bsw-entity=BswCE_Csm_KeyGenerate, swc-runnable=KeyGenerate
      bsw-entity=BswCE_Csm_KeyDerive, swc-runnable=KeyDerive
      bsw-entity=BswCE_Csm_KeyExchangeCalcPubVal, swc-runnable=KeyExchangeCalcPubVal
      bsw-entity=BswCE_Csm_KeyExchangeCalcSecret, swc-runnable=KeyExchangeCalcSecret
      bsw-entity=BswCE_Csm_RandomGenerate, swc-runnable=RandomGenerate
      bsw-entity=BswCE_Csm_CancelJob, swc-runnable=CancelJob
      bsw-entity=BswCE_Csm_SignatureVerify, swc-runnable=SignatureVerify
      bsw-entity=BswSE_Csm_MainFunction, swc-runnable=MainFunction
  swc implementation SwcImplementation_Csm: swc-bsw-mapping=SwcBswMapping_Csm, behavior=CsmInternalBehavior
